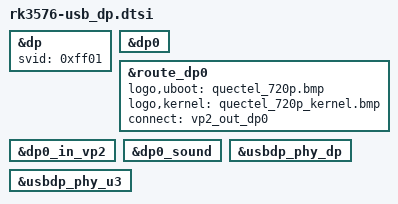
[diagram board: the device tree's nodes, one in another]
// SPDX-License-Identifier: (GPL-2.0+ OR MIT)

&dp {
	status = "okay";
	svid = <0xff01>;
};

&dp0 {
	status = "okay";
};

&route_dp0{
	status = "okay";
	logo,uboot = "quectel_720p.bmp";
    logo,kernel = "quectel_720p_kernel.bmp";
	connect = <&vp2_out_dp0>;
};

&dp0_in_vp2 {
	status = "okay";
};

&dp0_sound {
	status = "okay";
};

&usbdp_phy_dp {
	status = "okay";
};

&usbdp_phy_u3 {
	status = "okay";
};
